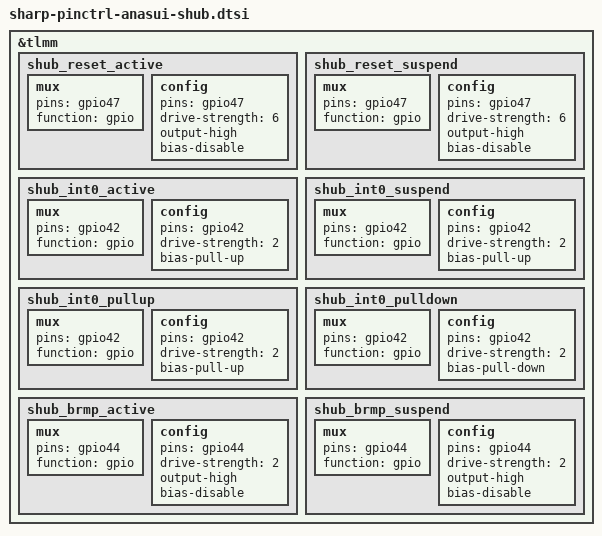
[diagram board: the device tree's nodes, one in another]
/* Copyright (c) 2013-2014, The Linux Foundation. All rights reserved.
 *
 * This program is free software; you can redistribute it and/or modify
 * it under the terms of the GNU General Public License version 2 and
 * only version 2 as published by the Free Software Foundation.
 *
 * This program is distributed in the hope that it will be useful,
 * but WITHOUT ANY WARRANTY; without even the implied warranty of
 * MERCHANTABILITY or FITNESS FOR A PARTICULAR PURPOSE.  See the
 * GNU General Public License for more details.
 */

&tlmm {
	/*****************************************/
	/*  pinctrl customize setting            */
	/*  SensorHub                            */
	/*****************************************/
	shub_reset_active: shub_reset_active {
		mux {
			pins = "gpio47";
			function = "gpio";
		};
		config {
			pins = "gpio47";
			drive-strength = <6>;
			output-high;
			bias-disable;
		};
	};
	shub_reset_suspend: shub_reset_suspend {
		mux {
			pins = "gpio47";
			function = "gpio";
		};
		config {
			pins = "gpio47";
			drive-strength = <6>;
			output-high;
			bias-disable;
		};
	};

	shub_int0_active: shub_int0_active {
		mux {
			pins = "gpio42";
			function = "gpio";
		};
		config {
			pins = "gpio42";
			drive-strength = <2>;
			bias-pull-up;
		};
	};
	shub_int0_suspend: shub_int0_suspend {
		mux {
			pins = "gpio42";
			function = "gpio";
		};
		config {
			pins = "gpio42";
			drive-strength = <2>;
			bias-pull-up;
		};
	};
	shub_int0_pullup: shub_int0_pullup {
		mux {
			pins = "gpio42";
			function = "gpio";
		};
		config {
			pins = "gpio42";
			drive-strength = <2>;
			bias-pull-up;
		};
	};
	shub_int0_pulldown: shub_int0_pulldown {
		mux {
			pins = "gpio42";
			function = "gpio";
		};
		config {
			pins = "gpio42";
			drive-strength = <2>;
			bias-pull-down;
		};
	};

	shub_brmp_active: shub_brmp_active {
		mux {
			pins = "gpio44";
			function = "gpio";
		};
		config {
			pins = "gpio44";
			drive-strength = <2>;
			output-high;
			bias-disable;
		};
	};
	shub_brmp_suspend: shub_brmp_suspend {
		mux {
			pins = "gpio44";
			function = "gpio";
		};
		config {
			pins = "gpio44";
			drive-strength = <2>;
			output-high;
			bias-disable;
		};
	};
};

